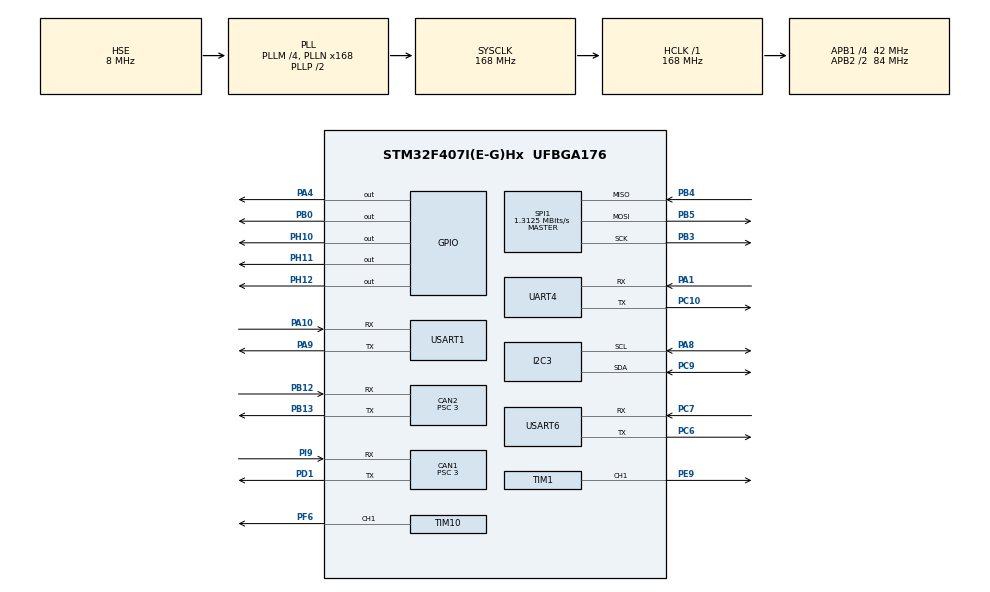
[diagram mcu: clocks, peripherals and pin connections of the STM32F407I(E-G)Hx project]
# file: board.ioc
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CAN1.BS1=CAN_BS1_10TQ
CAN1.BS2=CAN_BS2_3TQ
CAN1.CalculateBaudRate=1000000
CAN1.CalculateTimeBit=1000
CAN1.CalculateTimeQuantum=71.42857142857143
CAN1.Prescaler=3
CAN2.BS1=CAN_BS1_10TQ
CAN2.BS2=CAN_BS2_3TQ
CAN2.CalculateBaudRate=1000000
CAN2.CalculateTimeBit=1000
CAN2.CalculateTimeQuantum=71.42857142857143
CAN2.Prescaler=3
I2C3.I2C_Mode=I2C_Fast
Mcu.Family=STM32F4
Mcu.Name=STM32F407I(E-G)Hx
Mcu.Package=UFBGA176
NVIC.CAN1_RX0_IRQn=true\:0\:0\:false\:false\:true\:false\:true\:true\:true
NVIC.CAN2_RX0_IRQn=true\:0\:0\:false\:false\:true\:false\:true\:true\:true
NVIC.PriorityGroup=NVIC_PRIORITYGROUP_4
NVIC.TIM8_TRG_COM_TIM14_IRQn=true\:15\:0\:false\:false\:true\:false\:false\:true\:true
NVIC.TimeBase=TIM8_TRG_COM_TIM14_IRQn
NVIC.TimeBaseIP=TIM14
NVIC.USART1_IRQn=true\:0\:0\:false\:false\:true\:true\:true\:true\:true
NVIC.USART6_IRQn=true\:0\:0\:false\:false\:true\:true\:true\:true\:true
PA1.Mode=Asynchronous
PA1.Signal=UART4_RX
PA10.Mode=Asynchronous
PA10.Signal=USART1_RX
PA13.Mode=Serial_Wire
PA13.Signal=SYS_JTMS-SWDIO
PA14.Mode=Serial_Wire
PA14.Signal=SYS_JTCK-SWCLK
PA4.Signal=GPIO_Output
PA8.Mode=I2C
PA8.Signal=I2C3_SCL
PA9.Mode=Asynchronous
PA9.Signal=USART1_TX
PB0.Signal=GPIO_Output
PB12.Mode=CAN_Activate
PB12.Signal=CAN2_RX
PB13.Mode=CAN_Activate
PB13.Signal=CAN2_TX
PB3.Mode=Full_Duplex_Master
PB3.Signal=SPI1_SCK
PB4.Mode=Full_Duplex_Master
PB4.Signal=SPI1_MISO
PB5.Mode=Full_Duplex_Master
PB5.Signal=SPI1_MOSI
PC10.Mode=Asynchronous
PC10.Signal=UART4_TX
PC6.Mode=Asynchronous
PC6.Signal=USART6_TX
PC7.Mode=Asynchronous
PC7.Signal=USART6_RX
PC9.Mode=I2C
PC9.Signal=I2C3_SDA
PD1.Mode=CAN_Activate
PD1.Signal=CAN1_TX
PE9.Signal=S_TIM1_CH1
PF6.Signal=S_TIM10_CH1
PH0-OSC_IN.Mode=HSE-External-Oscillator
PH0-OSC_IN.Signal=RCC_OSC_IN
PH1-OSC_OUT.Mode=HSE-External-Oscillator
PH1-OSC_OUT.Signal=RCC_OSC_OUT
PH10.PinState=GPIO_PIN_SET
PH10.Signal=GPIO_Output
PH11.PinState=GPIO_PIN_SET
PH11.Signal=GPIO_Output
PH12.PinState=GPIO_PIN_SET
PH12.Signal=GPIO_Output
PI9.Mode=CAN_Activate
PI9.Signal=CAN1_RX
ProjectManager.HeapSize=0x200
ProjectManager.StackSize=0x800
ProjectManager.TargetToolchain=CMake
RCC.48MHZClocksFreq_Value=84000000
RCC.AHBFreq_Value=168000000
RCC.APB1CLKDivider=RCC_HCLK_DIV4
RCC.APB1Freq_Value=42000000
RCC.APB1TimFreq_Value=84000000
RCC.APB2CLKDivider=RCC_HCLK_DIV2
RCC.APB2Freq_Value=84000000
RCC.APB2TimFreq_Value=168000000
RCC.CortexFreq_Value=168000000
RCC.HCLKFreq_Value=168000000
RCC.HSE_VALUE=8000000
RCC.HSI_VALUE=16000000
RCC.LSE_VALUE=32768
RCC.PLLM=4
RCC.PLLN=168
RCC.PLLSourceVirtual=RCC_PLLSOURCE_HSE
RCC.SYSCLKFreq_VALUE=168000000
RCC.SYSCLKSource=RCC_SYSCLKSOURCE_PLLCLK
RCC.VCOOutputFreq_Value=336000000
SH.S_TIM10_CH1.0=TIM10_CH1,PWM Generation1 CH1
SH.S_TIM1_CH1.0=TIM1_CH1,PWM Generation1 CH1
SPI1.BaudRatePrescaler=SPI_BAUDRATEPRESCALER_64
SPI1.CalculateBaudRate=1.3125 MBits/s
SPI1.Direction=SPI_DIRECTION_2LINES
SPI1.Mode=SPI_MODE_MASTER
SPI1.VirtualType=VM_MASTER
STMicroelectronics.X-CUBE-AZRTOS-F4.1.1.0.TX_APP_MEM_POOL_SIZE=4096
STMicroelectronics.X-CUBE-AZRTOS-F4.1.1.0.TX_MINIMUM_STACK=200
STMicroelectronics.X-CUBE-AZRTOS-F4.1.1.0.TX_TIMER_PROCESS_IN_ISR=1
STMicroelectronics.X-CUBE-AZRTOS-F4.1.1.0.TX_TIMER_TICKS_PER_SECOND=1000
STMicroelectronics.X-CUBE-AZRTOS-F4.1.1.0.ThreadXCcRTOSJjThreadXJjCore=true
STMicroelectronics.X-CUBE-AZRTOS-F4.1.1.0_IsAnAzureRtosMw=true
TIM1.Channel-PWM\ Generation1\ CH1=TIM_CHANNEL_1
TIM1.Period=20000-1
TIM1.Prescaler=192-1
TIM10.Channel=TIM_CHANNEL_1
TIM10.Period=24999
UART4.VirtualMode=Asynchronous
USART1.VirtualMode=VM_ASYNC
USART6.VirtualMode=VM_ASYNC
VP_STMicroelectronics.X-CUBE-AZRTOS-F4_VS_RTOSJjThreadX_6.1.10_1.1.0.Mode=RTOSJjThreadX
VP_SYS_VS_tim14.Mode=TIM14
VP_TIM10_VS_ClockSourceINT.Mode=Enable_Timer
VP_TIM1_VS_ClockSourceINT.Mode=Internal
board=custom

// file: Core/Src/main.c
/* USER CODE BEGIN Header */
/**
  ******************************************************************************
  * @file           : main.c
  * @brief          : Main program body
  ******************************************************************************
  * @attention
  *
  * Copyright (c) 2026 STMicroelectronics.
  * All rights reserved.
  *
  * This software is licensed under terms that can be found in the LICENSE file
  * in the root directory of this software component.
  * If no LICENSE file comes with this software, it is provided AS-IS.
  *
  ******************************************************************************
  */
/* USER CODE END Header */
#include "app_threadx.h"
#include "main.h"
#include "can.h"
#include "i2c.h"
#include "spi.h"
#include "tim.h"
#include "usart.h"
#include "gpio.h"

/* USER CODE BEGIN Includes */
#include "bsp.hpp" /* [AI] 追加：bsp_Init() 的声明 */
/* USER CODE END Includes */

void SystemClock_Config(void);

int main(void)
{

  /* MCU Configuration--------------------------------------------------------*/

  /* Reset of all peripherals, Initializes the Flash interface and the Systick. */
  HAL_Init();

  /* Configure the system clock */
  SystemClock_Config();

  /* Initialize all configured peripherals */
  //MX_GPIO_Init();
  MX_CAN1_Init();
  MX_I2C3_Init();
  MX_SPI1_Init();
  MX_TIM1_Init();
  MX_UART4_Init();
  MX_CAN2_Init();
  MX_TIM10_Init();
  MX_USART1_UART_Init();
  MX_USART6_UART_Init();
  /* USER CODE BEGIN 2 */
  bsp_Init();
  // HAL_GPIO_WritePin(GPIOH, GPIO_PIN_11, GPIO_PIN_SET);
  // HAL_GPIO_WritePin(GPIOH, GPIO_PIN_12, GPIO_PIN_SET);
  /* USER CODE END 2 */

  MX_ThreadX_Init();

  /* We should never get here as control is now taken by the scheduler */

  /* Infinite loop */
  while (1)
  {

    // while(1)
    // {
    //   HAL_GPIO_TogglePin(GPIOH, GPIO_PIN_11);
    //   HAL_Delay(500);
    // }

  }
}

void SystemClock_Config(void)
{
  RCC_OscInitTypeDef RCC_OscInitStruct = {0};
  RCC_ClkInitTypeDef RCC_ClkInitStruct = {0};

  /** Configure the main internal regulator output voltage
  */
  __HAL_RCC_PWR_CLK_ENABLE();
  __HAL_PWR_VOLTAGESCALING_CONFIG(PWR_REGULATOR_VOLTAGE_SCALE1);

  /** Initializes the RCC Oscillators according to the specified parameters
  * in the RCC_OscInitTypeDef structure.
  */
  RCC_OscInitStruct.OscillatorType = RCC_OSCILLATORTYPE_HSE;
  RCC_OscInitStruct.HSEState = RCC_HSE_ON;
  RCC_OscInitStruct.PLL.PLLState = RCC_PLL_ON;
  RCC_OscInitStruct.PLL.PLLSource = RCC_PLLSOURCE_HSE;
  RCC_OscInitStruct.PLL.PLLM = 4;
  RCC_OscInitStruct.PLL.PLLN = 168;
  RCC_OscInitStruct.PLL.PLLP = RCC_PLLP_DIV2;
  RCC_OscInitStruct.PLL.PLLQ = 4;
  if (HAL_RCC_OscConfig(&RCC_OscInitStruct) != HAL_OK)
  {
    Error_Handler();
  }

  /** Initializes the CPU, AHB and APB buses clocks
  */
  RCC_ClkInitStruct.ClockType = RCC_CLOCKTYPE_HCLK|RCC_CLOCKTYPE_SYSCLK
                              |RCC_CLOCKTYPE_PCLK1|RCC_CLOCKTYPE_PCLK2;
  RCC_ClkInitStruct.SYSCLKSource = RCC_SYSCLKSOURCE_PLLCLK;
  RCC_ClkInitStruct.AHBCLKDivider = RCC_SYSCLK_DIV1;
  RCC_ClkInitStruct.APB1CLKDivider = RCC_HCLK_DIV4;
  RCC_ClkInitStruct.APB2CLKDivider = RCC_HCLK_DIV2;

  if (HAL_RCC_ClockConfig(&RCC_ClkInitStruct, FLASH_LATENCY_5) != HAL_OK)
  {
    Error_Handler();
  }
}

void HAL_TIM_PeriodElapsedCallback(TIM_HandleTypeDef *htim)
{
  if (htim->Instance == TIM14)
  {
    HAL_IncTick();
  }
}

void Error_Handler(void)
{
  __disable_irq();
  while (1)
  {
  }
}
